# CC1311P3 register map
File version: 1.0
CPU: CM4 1.0, other endian, MPU, FPU, 3 interrupt priority bits
Registers are 32-bit, read-write, reset 0x0 unless marked. A register's access mark holds for its fields unless they carry their own. Offsets are from the block's base; [hi:lo] are bit positions.

## AUX_SYSIF — AUX System Interface (AUX_SYSIF) is responsible for: - system resource requests, such as power supply and clock requests. - configuration of AUX peripheral operational rates for AUX_ANAIF DAC state machine and AUX_TIMER01. - configuration of event synchronization rate for AUX_EVCTL:EVSTAT2 and AUX_EVCTL:EVSTAT3. Peripheral operational rate for AUX modules mentioned above can either be: - SCE rate, which is configured in AON_PMCTL:AUXSCECLK. - AUX bus rate, which equals SCE rate or SCLK_HF divided by two when MCU domain is active or AUX operational mode is active. AUX_SYSIF also interfaces AON_RTC to enable read access to data and sub-second increment control of AON_RTC.
Base 0x400C6000
0x00 OPMODEREQ — Operational Mode Request AUX can operate in three operational modes. Each mode is associated with: - a SCE clock source or rate, given by AON_PMCTL:AUXSCECLK. This rate is termed SCE_RATE. - a system power supply state request. AUX can request powerdown (uLDO) or active (GLDO or DCDC) system power supply state. Follow these rules: - It is not allowed to change a request until it has been acknowledged through OPMODEACK. - A change in mode request must happen stepwise along this sequence, the direction is irrelevant: PDA - A - LP - PDLP. Failure to follow these rules might result in unexpected behavior and must be avoided.
  [1:0] REQ — [1:0] AUX operational mode request.
    3=PDLP (Powerdown operational mode with wakeup to lowpower mode, characterized by: - Powerdown system power supply state (uLDO) request. - AON_PMCTL:AUXSCECLK.PD_SRC sets the SCE clock frequency (SCE_RATE). - An active wakeup flag overrides the operational mode externally to lowpower (LP) as long as the flag is set.); 2=PDA (Powerdown operational mode with wakeup to active mode, characterized by: - Powerdown system power supply state (uLDO) request. - AON_PMCTL:AUXSCECLK.PD_SRC sets the SCE clock frequency (SCE_RATE). - An active wakeup flag overrides the operational mode externally to active (A) as long as the flag is set.); 1=LP (Lowpower operational mode, characterized by: - Powerdown system power supply state (uLDO) request. - SCE clock frequency (SCE_RATE) equals SCLK_MF. - An active wakeup flag does not change operational mode.); 0=A (Active operational mode, characterized by: - Active system power supply state (GLDO or DCDC) request. - AON_PMCTL:AUXSCECLK.SRC sets the SCE clock frequency (SCE_RATE). - An active wakeup flag does not change operational mode.)
0x04 OPMODEACK — Operational Mode Acknowledgement User must assume that the current operational mode is the one acknowledged.
  [1:0] ACK ro — [1:0] AUX operational mode acknowledgement.
    3=PDLP (Powerdown operational mode with wakeup to lowpower mode is acknowledged.); 2=PDA (Powerdown operational mode with wakeup to active mode is acknowledged.); 1=LP (Lowpower operational mode is acknowledged.); 0=A (Active operational mode is acknowledged.)
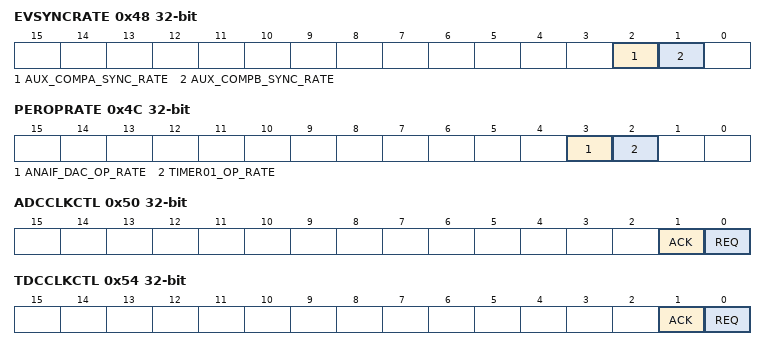
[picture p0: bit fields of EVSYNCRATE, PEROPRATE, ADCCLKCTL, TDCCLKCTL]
0x48 EVSYNCRATE — Event Synchronization Rate Configure synchronization rate for certain events to the synchronous AUX event bus. Select AUX bus rate when system CPU uses the event. SCE rate equals rate configured in AON_PMCTL:AUXSCECLK. AUX bus rate equals SCE rate, or SCLK_HF divided by two when MCU domain is active.
  [2] AUX_COMPA_SYNC_RATE — [2:2] Select synchronization rate for AUX_EVCTL:EVSTAT2.AUX_COMPA event.
    1=BUS_RATE (AUX bus rate); 0=SCE_RATE
  [1] AUX_COMPB_SYNC_RATE — [1:1] Select synchronization rate for AUX_EVCTL:EVSTAT2.AUX_COMPB event.
    1=BUS_RATE (AUX bus rate); 0=SCE_RATE
0x4C PEROPRATE — Peripheral Operational Rate Some AUX peripherals are operated at either SCE or at AUX bus rate. Select AUX bus rate when system CPU uses such peripheral. SCE rate equals rate configured in AON_PMCTL:AUXSCECLK. AUX bus rate equals SCE rate, or SCLK_HF divided by 2 when MCU domain is active.
  [3] ANAIF_DAC_OP_RATE — [3:3] Select operational rate for AUX_ANAIF DAC sample clock state machine.
    1=BUS_RATE (AUX bus rate); 0=SCE_RATE
  [2] TIMER01_OP_RATE — [2:2] Select operational rate for AUX_TIMER01.
    1=BUS_RATE (AUX bus rate); 0=SCE_RATE
0x50 ADCCLKCTL — ADC Clock Control
  [1] ACK ro — [1:1] Clock acknowledgement. 0: ADC clock is disabled. 1: ADC clock is enabled.
  [0] REQ — [0:0] ADC clock request. 0: Disable ADC clock. 1: Enable ADC clock. Only modify REQ when equal to ACK.
0x54 TDCCLKCTL — TDC Counter Clock Control Controls if the AUX_TDC counter clock source is enabled. These are the recommended steps to configure and request the counter clock: - Ensure that REQ=0 and ACK=0. - Configure clock source in DDI_0_OSC:CTL0.ACLK_TDC_SRC_SEL. - Read DDI_0_OSC:CTL0 to avoid a race condition between previous step and next step. - Set REQ=1 to request the clock. - Wait until ACK=1. After these steps ACK stays high until REQ=0. It is hence not recommended to reconfigure DDI_0_OSC:CTL0.ACLK_TDC_SRC_SEL when ACK=1. In this case, there will be no indication of when the new clock source selection is ready. These are the recommended steps to stop the counter clock: - Ensure that REQ=1 and ACK=1. - Set REQ=0 to stop the clock. - Wait until ACK=0.
  [1] ACK ro — [1:1] TDC counter clock acknowledgement. 0: TDC counter clock is disabled. 1: TDC counter clock is enabled.
  [0] REQ — [0:0] TDC counter clock request. 0: Disable TDC counter clock. 1: Enable TDC counter clock. Only modify REQ when equal to ACK.
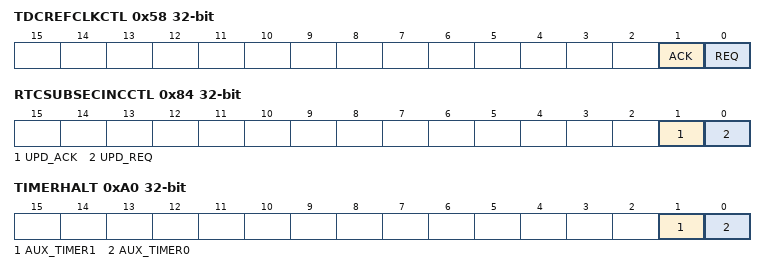
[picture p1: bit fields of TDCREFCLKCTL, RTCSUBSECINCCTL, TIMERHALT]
0x58 TDCREFCLKCTL — TDC Reference Clock Control Controls if the AUX_TDC reference clock source is enabled. These are the recommended steps to configure and request the reference clock: - Ensure that REQ=0 and ACK=0. - Configure clock source in DDI_0_OSC:CTL0.ACLK_REF_SRC_SEL. - Read DDI_0_OSC:CTL0 to avoid a race condition between previous step and next step. - Set REQ=1 to request the clock. - Wait until ACK=1. After these steps ACK stays high until REQ=0. It is hence not recommended to reconfigure DDI_0_OSC:CTL0.ACLK_REF_SRC_SEL when ACK=1. In this case, there will be no indication of when the new clock source selection is ready. These are the recommended steps to stop the reference clock: - Ensure that REQ=1 and ACK=1. - Set REQ=0 to stop the clock. - Wait until ACK=0.
  [1] ACK ro — [1:1] TDC reference clock acknowledgement. 0: TDC reference clock is disabled. 1: TDC reference clock is enabled.
  [0] REQ — [0:0] TDC reference clock request. 0: Disable TDC reference clock. 1: Enable TDC reference clock. Only modify REQ when equal to ACK.
0x7C RTCSUBSECINC0 — Real Time Counter Sub Second Increment 0 INC15_0 will replace bits 15:0 in AON_RTC:SUBSECINC when RTCSUBSECINCCTL.UPD_REQ is set.
  [15:0] INC15_0 — [15:0] New value for bits 15:0 in AON_RTC:SUBSECINC.
0x80 RTCSUBSECINC1 — Real Time Counter Sub Second Increment 1 INC23_16 will replace bits 23:16 in AON_RTC:SUBSECINC when RTCSUBSECINCCTL.UPD_REQ is set.
  [7:0] INC23_16 — [7:0] New value for bits 23:16 in AON_RTC:SUBSECINC.
0x84 RTCSUBSECINCCTL — Real Time Counter Sub Second Increment Control
  [1] UPD_ACK ro — [1:1] Update acknowledgement. 0: AON_RTC has not acknowledged UPD_REQ. 1: AON_RTC has acknowledged UPD_REQ.
  [0] UPD_REQ — [0:0] Request AON_RTC to update AON_RTC:SUBSECINC. 0: Clear request to update. 1: Set request to update. Only change UPD_REQ when it equals UPD_ACK. Clear UPD_REQ after UPD_ACK is 1.
0x90 RTCEVCLR — AON_RTC Event Clear Request to clear events: - AON_RTC:EVFLAGS.CH2. - AON_RTC:EVFLAGS.CH2 delayed version. - AUX_EVCTL:EVSTAT2.AON_RTC_CH2. - AUX_EVCTL:EVSTAT2.AON_RTC_CH2_DLY.
  [0] RTC_CH2_EV_CLR — [0:0] Clear events from AON_RTC channel 2. 0: No effect. 1: Clear events from AON_RTC channel 2. Keep RTC_CH2_EV_CLR high until AUX_EVCTL:EVSTAT2.AON_RTC_CH2 and AUX_EVCTL:EVSTAT2.AON_RTC_CH2_DLY are 0.
0xA0 TIMERHALT — Timer Halt Debug register
  [1] AUX_TIMER1 — [1:1] Halt AUX_TIMER01 Timer 1. 0: AUX_TIMER01 Timer 1 operates as normal. 1: Halt AUX_TIMER01 Timer 1 operation.
  [0] AUX_TIMER0 — [0:0] Halt AUX_TIMER01 Timer 0. 0: AUX_TIMER01 Timer 0 operates as normal. 1: Halt AUX_TIMER01 Timer 0 operation.
0xB4 SWPWRPROF — Software Power Profiler
  [2:0] STAT — [2:0] Software status bits that can be read by the power profiler.
